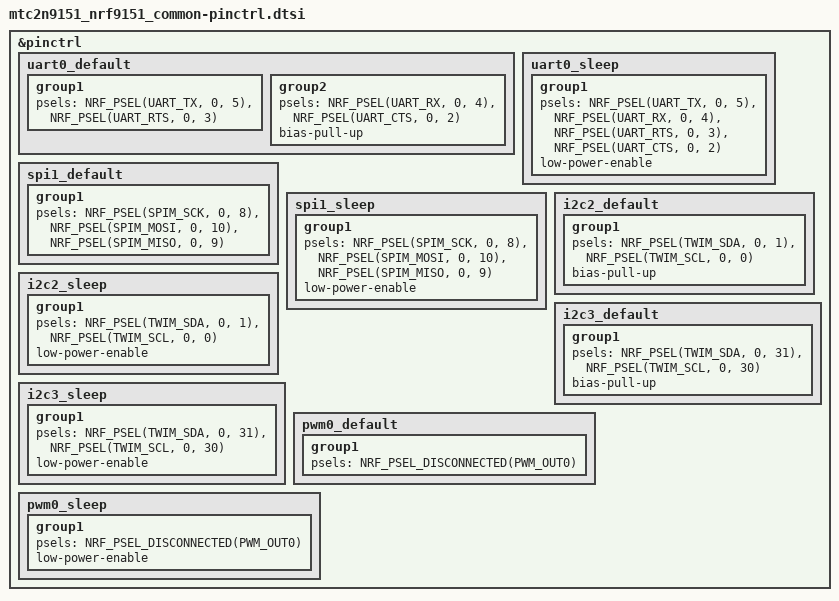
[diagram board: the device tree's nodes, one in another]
/*
 * Copyright (c) 2023 Nordic Semiconductor
 * Copyright 2025 LooUQ Incorporated
 * SPDX-License-Identifier: Apache-2.0
 */

&pinctrl {
	uart0_default: uart0_default {
		group1 {
			psels = <NRF_PSEL(UART_TX, 0, 5)>,
   				    <NRF_PSEL(UART_RTS, 0, 3)>;
		};
		group2 {
			psels = <NRF_PSEL(UART_RX, 0, 4)>,
				    <NRF_PSEL(UART_CTS, 0, 2)>;
			bias-pull-up;
		};

        // 	group1 {
        // 		psels = <NRF_PSEL_DISCONNECTED(UART_TX)>,
        // 			    <NRF_PSEL_DISCONNECTED(UART_RTS)>;
        // 	};
        // 	group2 {
        // 		psels = <NRF_PSEL_DISCONNECTED(UART_RX)>,
        // 			    <NRF_PSEL_DISCONNECTED(UART_CTS)>;
        // 		bias-pull-up;
        // 	};
    };

	uart0_sleep: uart0_sleep {
		group1 {
			psels = <NRF_PSEL(UART_TX, 0, 5)>,
				    <NRF_PSEL(UART_RX, 0, 4)>,
				    <NRF_PSEL(UART_RTS, 0, 3)>,
				    <NRF_PSEL(UART_CTS, 0, 2)>;
			low-power-enable;
		};

        // group1 {
		// 	psels = <NRF_PSEL_DISCONNECTED(UART_TX)>,
		// 		    <NRF_PSEL_DISCONNECTED(UART_RX)>,
		// 		    <NRF_PSEL_DISCONNECTED(UART_RTS)>,
		// 		    <NRF_PSEL_DISCONNECTED(UART_CTS)>;
		// 	low-power-enable;
		// };
	};

    /*
     * ----------------------------------------------------------------------------------------- */

	spi1_default: spi1_default {
		group1 {
            psels = <NRF_PSEL(SPIM_SCK, 0, 8)>,
                    <NRF_PSEL(SPIM_MOSI, 0, 10)>,
                    <NRF_PSEL(SPIM_MISO, 0, 9)>;
		};

        // group1 {
        //     psels = <NRF_PSEL_DISCONNECTED(SPIM_SCK)>,
        //             <NRF_PSEL_DISCONNECTED(SPIM_MOSI)>,
        //             <NRF_PSEL_DISCONNECTED(SPIM_MISO)>;
		// };
    };

	spi1_sleep: spi1_sleep {
		group1 {
            psels = <NRF_PSEL(SPIM_SCK, 0, 8)>,
                    <NRF_PSEL(SPIM_MOSI, 0, 10)>,
                    <NRF_PSEL(SPIM_MISO, 0, 9)>;
            low-power-enable;
		};

        // group1 {
        //     psels = <NRF_PSEL_DISCONNECTED(SPIM_SCK)>,
        //             <NRF_PSEL_DISCONNECTED(SPIM_MOSI)>,
        //             <NRF_PSEL_DISCONNECTED(SPIM_MISO)>;
        //     low-power-enable;
		// };
    };

    /*
     * ----------------------------------------------------------------------------------------- */

    i2c2_default: i2c2_default {
		group1 {
			psels = <NRF_PSEL(TWIM_SDA, 0, 1)>,
				    <NRF_PSEL(TWIM_SCL, 0, 0)>;
                    bias-pull-up;
		};

		// group1 {
		// 	psels = <NRF_PSEL_DISCONNECTED(TWIM_SDA)>,
 		// 		    <NRF_PSEL_DISCONNECTED(TWIM_SCL)>;
		// };
    };

	i2c2_sleep: i2c2_sleep {
		group1 {
			psels = <NRF_PSEL(TWIM_SDA, 0, 1)>,
				    <NRF_PSEL(TWIM_SCL, 0, 0)>;
			low-power-enable;
		};

		// group1 {
		// 	psels = <NRF_PSEL_DISCONNECTED(TWIM_SDA)>,
		// 		    <NRF_PSEL_DISCONNECTED(TWIM_SCL)>;
		// 	low-power-enable;
		// };
    };

    /*
     * ----------------------------------------------------------------------------------------- */

    /* I2C3 is used by the host-extension (HX) interface
     * on most LooUQ platform hosts (LQnode, etc.)
     *
     * It is aliased to hostext 
     */
    i2c3_default: i2c3_default {
		group1 {
			psels = <NRF_PSEL(TWIM_SDA, 0, 31)>,
				    <NRF_PSEL(TWIM_SCL, 0, 30)>;
                    bias-pull-up;
		};
		// group1 {
		// 	psels = <NRF_PSEL_DISCONNECTED(TWIM_SDA)>,
		// 		    <NRF_PSEL_DISCONNECTED(TWIM_SCL)>;
		// };
    };

	i2c3_sleep: i2c3_sleep {
		group1 {
			psels = <NRF_PSEL(TWIM_SDA, 0, 31)>,
				    <NRF_PSEL(TWIM_SCL, 0, 30)>;
			low-power-enable;
		};
		// group1 {
		// 	psels = <NRF_PSEL_DISCONNECTED(TWIM_SDA)>,
		// 		    <NRF_PSEL_DISCONNECTED(TWIM_SCL)>;
		// 	low-power-enable;
		// };
    };

    /*
     * ----------------------------------------------------------------------------------------- */

	pwm0_default: pwm0_default {
		// group1 {
		// 	psels = <NRF_PSEL(PWM_OUT0, 0, 26)>;
		// };

        group1 {
		    psels = <NRF_PSEL_DISCONNECTED(PWM_OUT0)>;
    	};
	};

	pwm0_sleep: pwm0_sleep {
		// group1 {
		// 	psels = <NRF_PSEL(PWM_OUT0, 0, 26)>;
		// 	low-power-enable;
		// };

		group1 {
			psels = <NRF_PSEL_DISCONNECTED(PWM_OUT0)>;
			low-power-enable;
		};
    };
};

